CM_ "AUTOGENERATED FILE, DO NOT EDIT"

CM_ "Imported file _toyota_2017.dbc starts here"
VERSION ""

BS_:

BU_: XXX DSU HCU EPS IPAS

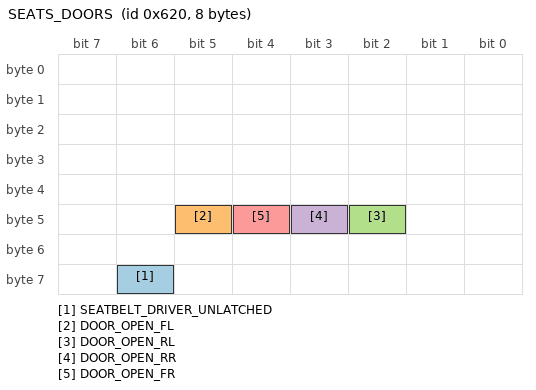
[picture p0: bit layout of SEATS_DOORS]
BO_ 1568 SEATS_DOORS: 8 XXX
 SG_ SEATBELT_DRIVER_UNLATCHED : 62|1@0+ (1,0) [0|1] "" XXX
 SG_ DOOR_OPEN_FL : 45|1@0+ (1,0) [0|1] "" XXX
 SG_ DOOR_OPEN_RL : 42|1@0+ (1,0) [0|1] "" XXX
 SG_ DOOR_OPEN_RR : 43|1@0+ (1,0) [0|1] "" XXX
 SG_ DOOR_OPEN_FR : 44|1@0+ (1,0) [0|1] "" XXX

VAL_ 466 CRUISE_STATE 8 "active" 7 "standstill" 1 "off" ;
 "faulted";
